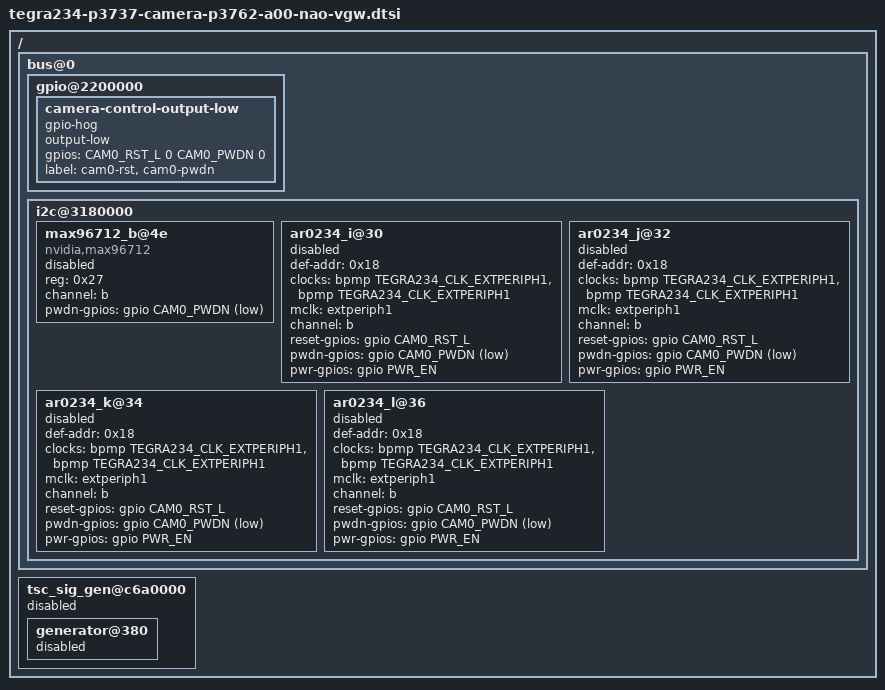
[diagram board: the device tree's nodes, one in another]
// SPDX-License-Identifier: GPL-2.0-only
// SPDX-FileCopyrightText: Copyright (c) 2024, NVIDIA CORPORATION & AFFILIATES. All rights reserved.

#include "tegra234-camera-p3762-a00-nao-vgw.dtsi"
#include "dt-bindings/gpio/tegra234-gpio.h"
#include "dt-bindings/clock/tegra234-clock.h"
#include <dt-bindings/tegra234-p3737-0000+p3701-0000.h>

/* camera control gpio definitions */
#define CAM0_RST_L      TEGRA234_MAIN_GPIO(H, 3) //UART4_TX(L5) on CVM
#define CAM0_PWDN       TEGRA234_MAIN_GPIO(H, 6) //UART4_CTS(L49) on CVM
//#define CAM1_RST_L      TEGRA234_MAIN_GPIO(AC, 1)
//#define CAM1_PWDN       TEGRA234_MAIN_GPIO(AC, 0) //GPIO15(F10) on CVM
#define PWR_EN      TEGRA234_MAIN_GPIO(AC, 7)
#define GYRO1_IRQ_GPIO  TEGRA234_AON_GPIO(CC, 1)
#define ACCE1_IRQ_GPIO  TEGRA234_AON_GPIO(CC, 0)

/ {
	fragment-camera-hawk-owl@0 {
		target-path = "/";
		__overlay__ {
			bus@0 {
				/* set camera gpio direction to output */
				gpio@2200000 {
					camera-control-output-low {
						gpio-hog;
						output-low;
						gpios = <CAM0_RST_L 0 CAM0_PWDN 0>;
						label = "cam0-rst", "cam0-pwdn";
					};
				};
				i2c@3180000 {
					max96712_b@4e {
						compatible = "nvidia,max96712";
						reg = <0x27>;
						channel = "b";
						pwdn-gpios = <&gpio CAM0_PWDN GPIO_ACTIVE_LOW>;
						status = "disabled";
					};
					ar0234_i@30 {
						status = "disabled";
						def-addr = <0x18>;
						/* Define any required hw resources needed by driver */
						/* ie. clocks, io pins, power sources */
						clocks = <&bpmp TEGRA234_CLK_EXTPERIPH1>,
								<&bpmp TEGRA234_CLK_EXTPERIPH1>;
						clock-names = "extperiph1", "pllp_grtba";
						mclk = "extperiph1";
						channel = "b";
//						has-eeprom;
//						eeprom-addr = <0x38>;
						reset-gpios = <&gpio CAM0_RST_L GPIO_ACTIVE_HIGH>;
						pwdn-gpios = <&gpio CAM0_PWDN GPIO_ACTIVE_LOW>;
						pwr-gpios = <&gpio PWR_EN GPIO_ACTIVE_HIGH>;
					};
					ar0234_j@32 {
						status = "disabled";
						def-addr = <0x18>;
						/* Define any required hw resources needed by driver */
						/* ie. clocks, io pins, power sources */
						clocks = <&bpmp TEGRA234_CLK_EXTPERIPH1>,
								<&bpmp TEGRA234_CLK_EXTPERIPH1>;
						clock-names = "extperiph1", "pllp_grtba";
						mclk = "extperiph1";
						channel = "b";
//						has-eeprom;
//						eeprom-addr = <0x3a>;
						reset-gpios = <&gpio CAM0_RST_L GPIO_ACTIVE_HIGH>;
						pwdn-gpios = <&gpio CAM0_PWDN GPIO_ACTIVE_LOW>;
						pwr-gpios = <&gpio PWR_EN GPIO_ACTIVE_HIGH>;
					};
					ar0234_k@34 {
						status = "disabled";
						def-addr = <0x18>;
						/* Define any required hw resources needed by driver */
						/* ie. clocks, io pins, power sources */
						clocks = <&bpmp TEGRA234_CLK_EXTPERIPH1>,
								<&bpmp TEGRA234_CLK_EXTPERIPH1>;
						clock-names = "extperiph1", "pllp_grtba";
						mclk = "extperiph1";
						channel = "b";
//						has-eeprom;
//						eeprom-addr = <0x3c>;
						reset-gpios = <&gpio CAM0_RST_L GPIO_ACTIVE_HIGH>;
						pwdn-gpios = <&gpio CAM0_PWDN GPIO_ACTIVE_LOW>;
						pwr-gpios = <&gpio PWR_EN GPIO_ACTIVE_HIGH>;
					};
					ar0234_l@36 {
						status = "disabled";
						def-addr = <0x18>;
						/* Define any required hw resources needed by driver */
						/* ie. clocks, io pins, power sources */
						clocks = <&bpmp TEGRA234_CLK_EXTPERIPH1>,
								<&bpmp TEGRA234_CLK_EXTPERIPH1>;
						clock-names = "extperiph1", "pllp_grtba";
						mclk = "extperiph1";
						channel = "b";
//						has-eeprom;
//						eeprom-addr = <0x3e>;
						reset-gpios = <&gpio CAM0_RST_L GPIO_ACTIVE_HIGH>;
						pwdn-gpios = <&gpio CAM0_PWDN GPIO_ACTIVE_LOW>;
						pwr-gpios = <&gpio PWR_EN GPIO_ACTIVE_HIGH>;
					};
				};
			};
		};
	};
	fragment-cam-cdi-tsc@0 {
		target-path = "/";
		__overlay__ {
			tsc_sig_gen@c6a0000 {
				status = "disabled";
				generator@380 {
					status = "disabled";
				};
			};
		};
	};
};
